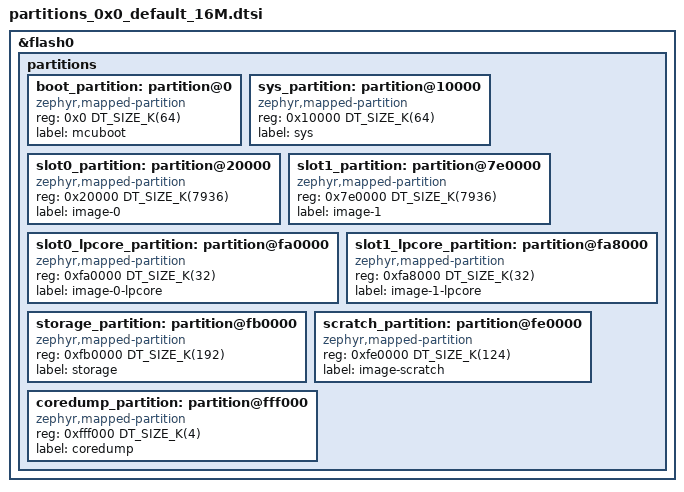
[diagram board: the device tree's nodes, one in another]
/*
 * Copyright (c) 2024-2025 Espressif Systems (Shanghai) Co., Ltd.
 *
 * SPDX-License-Identifier: Apache-2.0
 */

&flash0 {
	partitions {
		ranges;
		#address-cells = <1>;
		#size-cells = <1>;

		boot_partition: partition@0 {
			compatible = "zephyr,mapped-partition";
			reg = <0x0 DT_SIZE_K(64)>;
			label = "mcuboot";
		};

		sys_partition: partition@10000 {
			compatible = "zephyr,mapped-partition";
			reg = <0x10000 DT_SIZE_K(64)>;
			label = "sys";
		};

		slot0_partition: partition@20000 {
			compatible = "zephyr,mapped-partition";
			reg = <0x20000 DT_SIZE_K(7936)>;
			label = "image-0";
		};

		slot1_partition: partition@7e0000 {
			compatible = "zephyr,mapped-partition";
			reg = <0x7e0000 DT_SIZE_K(7936)>;
			label = "image-1";
		};

		slot0_lpcore_partition: partition@fa0000 {
			compatible = "zephyr,mapped-partition";
			reg = <0xfa0000 DT_SIZE_K(32)>;
			label = "image-0-lpcore";
		};

		slot1_lpcore_partition: partition@fa8000 {
			compatible = "zephyr,mapped-partition";
			reg = <0xfa8000 DT_SIZE_K(32)>;
			label = "image-1-lpcore";
		};

		storage_partition: partition@fb0000 {
			compatible = "zephyr,mapped-partition";
			reg = <0xfb0000 DT_SIZE_K(192)>;
			label = "storage";
		};

		scratch_partition: partition@fe0000 {
			compatible = "zephyr,mapped-partition";
			reg = <0xfe0000 DT_SIZE_K(124)>;
			label = "image-scratch";
		};

		coredump_partition: partition@fff000 {
			compatible = "zephyr,mapped-partition";
			reg = <0xfff000 DT_SIZE_K(4)>;
			label = "coredump";
		};
	};
};

/* Remaining flash size is 0kB
 * Last used address is 0xFFFFFF
 */
